VERSION ""

NS_ :

BS_:

BU_: PWM_NODE COMMANDER LISTENER REQUESTER

BO_ 32 state: 2 PWM_NODE
 SG_ system_state : 0|8@1+ (1,0) [0|255] ""  LISTENER
 SG_ mcu_temperature : 8|8@1+ (1,-40) [-40|215] "degC"  LISTENER

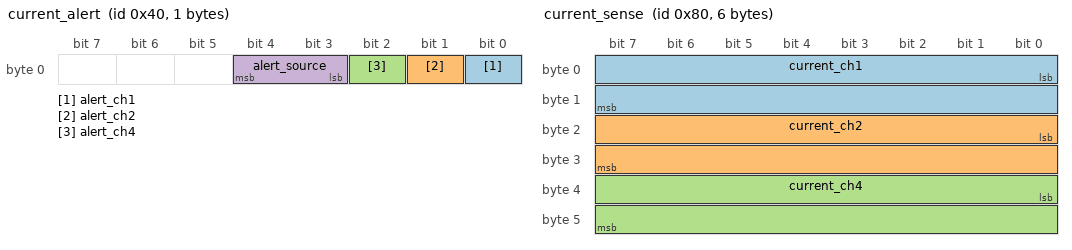
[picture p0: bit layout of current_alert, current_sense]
BO_ 64 current_alert: 1 PWM_NODE
 SG_ alert_ch1 : 0|1@1+ (1,0) [0|1] ""  LISTENER
 SG_ alert_ch2 : 1|1@1+ (1,0) [0|1] ""  LISTENER
 SG_ alert_ch4 : 2|1@1+ (1,0) [0|1] ""  LISTENER
 SG_ alert_source : 3|2@1+ (1,0) [0|2] ""  LISTENER

BO_ 96 command_servo: 4 COMMANDER
 SG_ node_id : 0|8@1+ (1,0) [0|255] ""  PWM_NODE
 SG_ servo_channel M : 8|3@1+ (1,0) [0|7] ""  PWM_NODE
 SG_ reserved0 : 11|5@1+ (1,0) [0|31] ""  PWM_NODE
 SG_ target_ch1 m1 : 16|16@1+ (1,0) [0|65535] "us"  PWM_NODE
 SG_ target_ch2 m2 : 16|16@1+ (1,0) [0|65535] "us"  PWM_NODE
 SG_ target_ch3 m3 : 16|16@1+ (1,0) [0|65535] "us"  PWM_NODE
 SG_ target_ch4 m4 : 16|16@1+ (1,0) [0|65535] "us"  PWM_NODE

BO_ 128 current_sense: 6 PWM_NODE
 SG_ current_ch1 : 0|16@1+ (1,0) [0|65535] "mA"  LISTENER
 SG_ current_ch2 : 16|16@1+ (1,0) [0|65535] "mA"  LISTENER
 SG_ current_ch4 : 32|16@1+ (1,0) [0|65535] "mA"  LISTENER

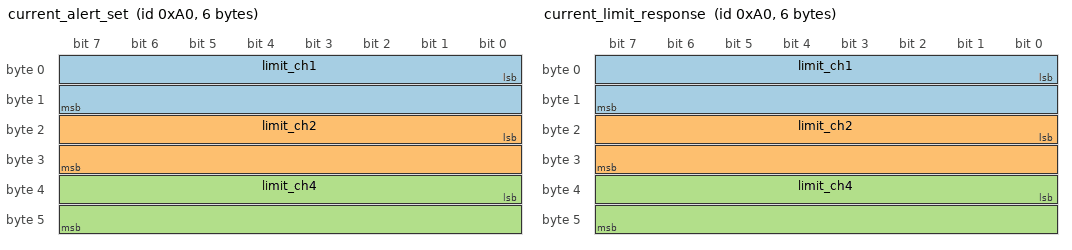
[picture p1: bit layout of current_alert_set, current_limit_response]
BO_ 160 current_alert_set: 6 COMMANDER
 SG_ limit_ch1 : 0|16@1+ (1,0) [0|65535] "mA"  PWM_NODE
 SG_ limit_ch2 : 16|16@1+ (1,0) [0|65535] "mA"  PWM_NODE
 SG_ limit_ch4 : 32|16@1+ (1,0) [0|65535] "mA"  PWM_NODE

BO_ 160 current_limit_get: 0 REQUESTER

BO_ 160 current_limit_response: 6 PWM_NODE
 SG_ limit_ch1 : 0|16@1+ (1,0) [0|65535] "mA"  REQUESTER
 SG_ limit_ch2 : 16|16@1+ (1,0) [0|65535] "mA"  REQUESTER
 SG_ limit_ch4 : 32|16@1+ (1,0) [0|65535] "mA"  REQUESTER

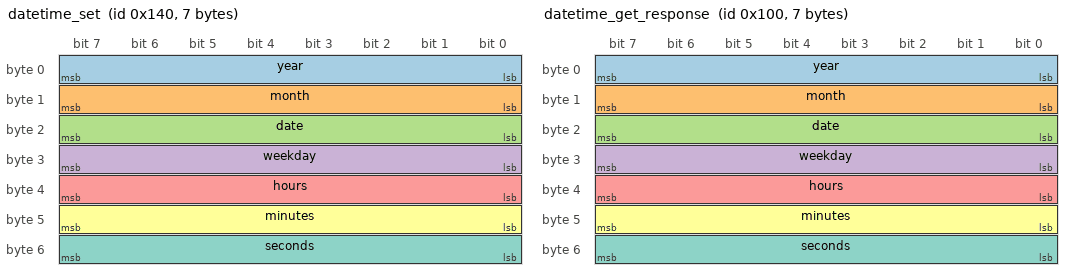
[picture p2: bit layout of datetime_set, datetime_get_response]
BO_ 320 datetime_set: 7 COMMANDER
 SG_ year : 0|8@1+ (1,0) [0|99] "year"  PWM_NODE
 SG_ month : 8|8@1+ (1,0) [1|12] "month"  PWM_NODE
 SG_ date : 16|8@1+ (1,0) [1|31] "day"  PWM_NODE
 SG_ weekday : 24|8@1+ (1,0) [1|7] "weekday"  PWM_NODE
 SG_ hours : 32|8@1+ (1,0) [0|23] "hour"  PWM_NODE
 SG_ minutes : 40|8@1+ (1,0) [0|59] "min"  PWM_NODE
 SG_ seconds : 48|8@1+ (1,0) [0|59] "sec"  PWM_NODE

BO_ 224 datetime_get: 0 REQUESTER

BO_ 256 datetime_get_response: 7 PWM_NODE
 SG_ year : 0|8@1+ (1,0) [0|99] "year"  REQUESTER
 SG_ month : 8|8@1+ (1,0) [1|12] "month"  REQUESTER
 SG_ date : 16|8@1+ (1,0) [1|31] "day"  REQUESTER
 SG_ weekday : 24|8@1+ (1,0) [1|7] "weekday"  REQUESTER
 SG_ hours : 32|8@1+ (1,0) [0|23] "hour"  REQUESTER
 SG_ minutes : 40|8@1+ (1,0) [0|59] "min"  REQUESTER
 SG_ seconds : 48|8@1+ (1,0) [0|59] "sec"  REQUESTER

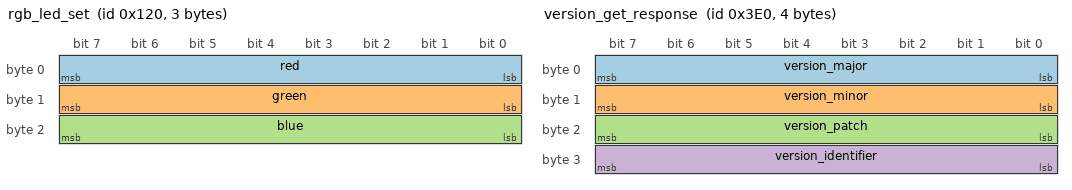
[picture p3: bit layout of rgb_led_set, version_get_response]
BO_ 288 rgb_led_set: 3 REQUESTER
 SG_ red : 0|8@1+ (1,0) [0|255] ""  PWM_NODE
 SG_ green : 8|8@1+ (1,0) [0|255] ""  PWM_NODE
 SG_ blue : 16|8@1+ (1,0) [0|255] ""  PWM_NODE

BO_ 960 version_get: 0 REQUESTER

BO_ 992 version_get_response: 4 PWM_NODE
 SG_ version_major : 0|8@1+ (1,0) [0|255] "major"  REQUESTER
 SG_ version_minor : 8|8@1+ (1,0) [0|255] "minor"  REQUESTER
 SG_ version_patch : 16|8@1+ (1,0) [0|255] "patch"  REQUESTER
 SG_ version_identifier : 24|8@1+ (1,0) [0|255] "ascii"  REQUESTER

BA_DEF_  "BusType" STRING ;
BA_DEF_DEF_  "BusType" "CAN";
